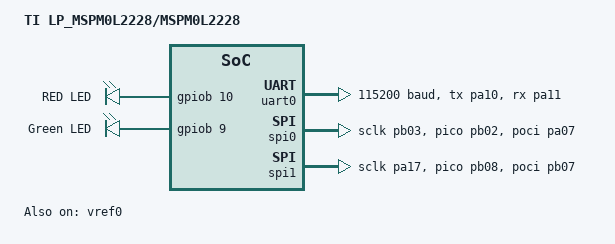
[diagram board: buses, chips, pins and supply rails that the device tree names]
/*
 * Copyright (c) 2025 Texas Instruments
 * Copyright (c) 2025 Linumiz GmbH
 *
 * SPDX-License-Identifier: Apache-2.0
 */

/dts-v1/;

#include <ti/mspm0/l/mspm0l2228.dtsi>
#include <ti/mspm0/l/mspm0l222x-pinctrl.dtsi>
#include <zephyr/dt-bindings/clock/mspm0_clock.h>
#include <zephyr/dt-bindings/gpio/gpio.h>

/ {
	compatible = "ti,mspm0l2228";
	model = "TI LP_MSPM0L2228/MSPM0L2228";

	aliases {
		led0 = &led0;
		led1 = &led1;
	};

	chosen {
		zephyr,sram = &sram0;
		zephyr,flash = &flash0;
		zephyr,console = &uart0;
		zephyr,shell-uart = &uart0;
		zephyr,code-partition = &slot0_partition;
	};

	leds {
		compatible = "gpio-leds";

		led0: led_0 {
			gpios = <&gpiob 10 GPIO_ACTIVE_HIGH>;
			label = "RED LED";
		};

		led1: led_1 {
			gpios = <&gpiob 9 GPIO_ACTIVE_HIGH>;
			label = "Green LED";
		};
	};
};

&flash0 {
	status = "okay";

	partitions {
		compatible = "fixed-partitions";
		#address-cells = <1>;
		#size-cells = <1>;

		boot_partition: partition@0 {
			reg = <0x00000000 0x8000>;
			label = "mcuboot";
		};

		slot0_partition: partition@8000 {
			reg = <0x00008000 0x1c000>;
			label = "image-0";
		};

		slot1_partition: partition@24000 {
			reg = <0x00024000 0x1c000>;
			label = "image-1";
		};
	};
};

&pinctrl {
	status = "okay";
};

&gpioa {
	status = "okay";
};

&gpiob {
	status = "okay";
};

&uart0 {
	current-speed = <115200>;
	pinctrl-0 = <&uart0_tx_pa10 &uart0_rx_pa11>;
	pinctrl-names = "default";
	status = "okay";
};

&spi0 {
	pinctrl-0 = <&spi0_sclk_pb03 &spi0_pico_pb02 &spi0_poci_pa07>;
	pinctrl-names = "default";
	cs-gpios = <&gpioa 8 GPIO_ACTIVE_LOW>;
	#address-cells = <1>;
	#size-cells = <0>;
	clocks = <&ckm MSPM0_CLOCK_MCLK>;
	status = "okay";
};

&spi1 {
	pinctrl-0 = <&spi1_sclk_pa17 &spi1_pico_pb08 &spi1_poci_pb07>;
	pinctrl-names = "default";
	cs-gpios = <&gpiob 6 GPIO_ACTIVE_LOW>;
	#address-cells = <1>;
	#size-cells = <0>;
	clocks = <&ckm MSPM0_CLOCK_MCLK>;
	status = "okay";
};

&vref0 {
	pinctrl-0 = <&analog_pa23>;
	pinctrl-names = "default";
	status = "okay";
};
